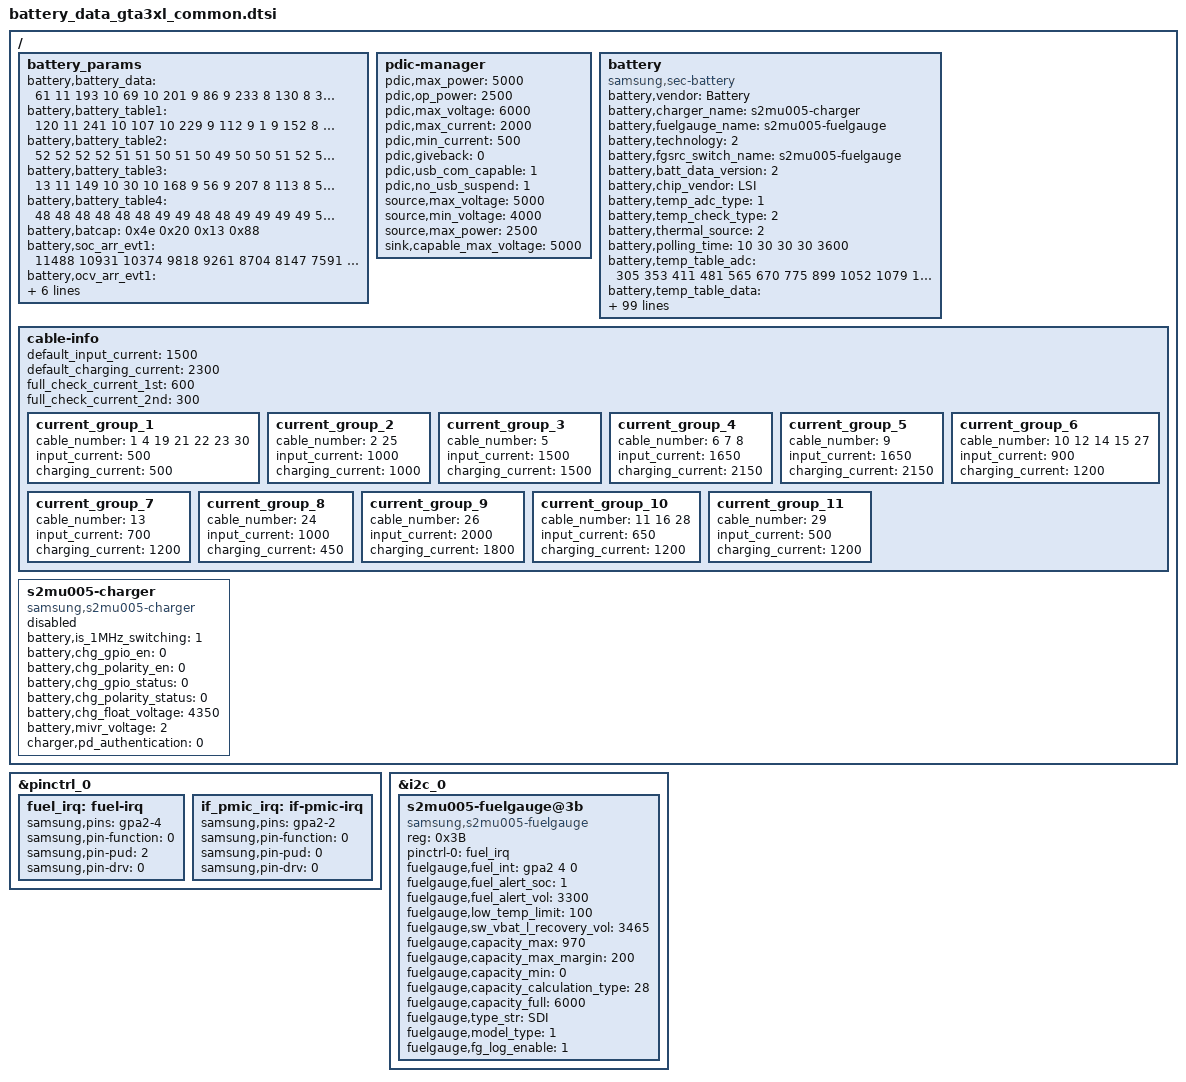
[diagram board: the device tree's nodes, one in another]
/*
 * Tab A3 2019 Battery parameters device tree file for board IDs 04 and higher
 *
 * Copyright (C) 2017 Samsung Electronics, Inc.
 *
 * This program is free software; you can redistribute it and/or
 * modify it under the terms of the GNU General Public License
 * as published by the Free Software Foundation; either version 2
 * of the License, or (at your option) any later version.
 *
 * This program is distributed in the hope that it will be useful,
 * but WITHOUT ANY WARRANTY; without even the implied warranty of
 * MERCHANTABILITY or FITNESS FOR A PARTICULAR PURPOSE.  See the
 * GNU General Public License for more details.
 *
 * You should have received a copy of the GNU General Public License
 * along with this program. If not, see <http://www.gnu.org/licenses/>.
 *
 */

/ {
	fragment@battery {
		target-path = "/";
		__overlay__ {
			battery_params {
					battery,battery_data =
					<
						/***** battery data for 4.35 *****/
						/* battery,battery_table3 */
						61 11 193 10 69 10 201 9 86 9
						233 8 130 8 34 8 204 7 116 7
						21 7 204 6 155 6 117 6 86 6
						58 6 20 6 238 5 183 5 139 5
						11 5 131 1 213 8 104 8 251 7
						142 7 33 7 180 6 71 6 218 5
						110 5 1 5 148 4 39 4 186 3
						77 3 224 2 115 2 7 2 154 1
						45 1 192 0 83 0 230 15

						/* battery,battery_table4 */
						10 10 10 10 10 10 96 97 96 96
						96 96 97 98 100 101 104 107 113 124
						138 86

						/* battery,batcap */
						0x5A 0x28 0x16 0x8A /* [0x0F] [0x0E] [0x11] [0x10] */
						/* battery,accum */
						0x00 0x8 /* [0x44] [0x45] */

						/* battery,soc_arr_val */
						11037 10506 9975 9443 8911 8380 7848 7317 6785 6253
						5722 5190 4659 4127 3595 3064 2532 2001 1469 937
						406 (-126)

						/* battery,ocv_arr_val */
						44046 43441 42835 42234 41670 41137 40637 40168 39748 39315
						38854 38497 38258 38072 37921 37782 37600 37410 37146 36928
						36302 31892

						/* battery,tunning */
						0x00

						/***** battery data for 4.33 *****/
						/* battery,battery_table3 */
						61 11 193 10 69 10 201 9 86 9
						233 8 130 8 34 8 204 7 116 7
						21 7 204 6 155 6 117 6 86 6
						58 6 20 6 238 5 183 5 139 5
						11 5 131 1 249 8 139 8 28 8
						174 7 63 7 209 6 98 6 244 5
						133 5 22 5 168 4 58 4 203 3
						93 3 238 2 127 2 17 2 162 1
						52 1 197 0 87 0 232 15

						/* battery,battery_table4 */
						51 51 97 97 97 97 96 97 96 96
						96 96 97 98 100 101 104 107 113 124
						138 206

						/* battery,batcap */
						0x59 0x10 0x16 0x44 /* [0x0F] [0x0E] [0x11] [0x10] */
						/* battery,accum */
						0x00 0x8 /* [0x44] [0x45] */

						/* battery,soc_arr_val */
						11217 10678 10138 9599 9059 8519 7980 7440 6899 6360
						5820 5281 4741 4202 3662 3122 2582 2043 1503 963
						423 (-115)
						/* battery,ocv_arr_val */
						44046 43441 42835 42234 41670 41137 40637 40168 39748 39315
						38854 38497 38258 38072 37921 37782 37600 37410 37146 36928
						36302 31892

						/* battery,tunning */
						0x00

						/***** battery data for 4.31 *****/
						/* battery,battery_table3 */
						61 11 193 10 69 10 201 9 86 9
						233 8 130 8 34 8 204 7 116 7
						21 7 204 6 155 6 117 6 86 6
						58 6 20 6 238 5 183 5 139 5
						11 5 131 1 54 9 196 8 83 8
						225 7 112 7 255 6 141 6 28 6
						170 5 57 5 199 4 86 4 229 3
						115 3 2 3 144 2 31 2 173 1
						60 1 202 0 89 0 232 15

						/* battery,battery_table4 */
						51 51 97 97 97 97 96 97 96 96
						96 96 97 98 100 101 104 107 113 124
						138 206

						/* battery,batcap */
						0x57 0x80 0x15 0xE0 /* [0x0F] [0x0E] [0x11] [0x10] */
						/* battery,accum */
						0x00 0x8 /* [0x44] [0x45] */

						/* battery,soc_arr_val */
						11512 10958 10404 9850 9297 8743 8189 7635 7080 6526
						5973 5419 4866 4312 3758 3204 2650 2096 1542 988
						434 (-119)
						/* battery,ocv_arr_val */
						44046 43441 42835 42234 41670 41137 40637 40168 39748 39315
						38854 38497 38258 38072 37921 37782 37600 37410 37146 36928
						36302 31892

						/* battery,tunning */
						0x00

						/***** battery data for 4.29 *****/
						/* battery,battery_table3 */
						61 11 193 10 69 10 201 9 86 9
						233 8 130 8 34 8 204 7 116 7
						21 7 204 6 155 6 117 6 86 6
						58 6 20 6 238 5 183 5 139 5
						11 5 131 1 155 9 37 9 174 8
						56 8 194 7 75 7 213 6 95 6
						232 5 114 5 252 4 133 4 15 4
						153 3 35 3 172 2 54 2 192 1
						73 1 211 0 93 0 231 15

						/* battery,battery_table4 */
						51 51 97 97 97 97 96 97 96 96
						96 96 97 98 100 101 104 107 113 124
						138 206

						/* battery,batcap */
						0x55 0xF0 0x15 0x7C /* [0x0F] [0x0E] [0x11] [0x10] */
						/* battery,accum */
						0x00 0x8 /* [0x44] [0x45] */

						/* battery,soc_arr_val */
						12007 11429 10851 10274 9696 9118 8541 7963 7385 6808
						6230 5652 5074 4497 3919 3342 2764 2186 1608 1031
						453 (-124)
						/* battery,ocv_arr_val */
						44046 43441 42835 42234 41670 41137 40637 40168 39748 39315
						38854 38497 38258 38072 37921 37782 37600 37410 37146 36928
						36302 31892

						/* battery,tunning */
						0x00

						/***** battery data for 4.24 *****/
						/* battery,battery_table3 */
						61 11 193 10 69 10 201 9 86 9
						233 8 130 8 34 8 204 7 116 7
						21 7 204 6 155 6 117 6 86 6
						58 6 20 6 238 5 183 5 139 5
						11 5 131 1 229 9 107 9 241 8
						120 8 254 7 132 7 10 7 144 6
						22 6 156 5 34 5 169 4 47 4
						181 3 59 3 193 2 71 2 205 1
						83 1 217 0 96 0 230 15

						/* battery,battery_table4 */
						51 51 97 97 97 97 96 97 96 96
						96 96 97 98 100 101 104 107 113 124
						138 206

						/* battery,batcap */
						0x52 0xD0 0x14 0xB4 /* [0x0F] [0x0E] [0x11] [0x10] */
						/* battery,accum */
						0x00 0x8 /* [0x44] [0x45] */

						/* battery,soc_arr_val */
						12369 11774 11178 10584 9988 9393 8798 8203 7608 7013
						6418 5823 5228 4633 4037 3442 2847 2252 1656 1062
						467 (-128)
						/* battery,ocv_arr_val */
						44046 43441 42835 42234 41670 41137 40637 40168 39748 39315
						38854 38497 38258 38072 37921 37782 37600 37410 37146 36928
						36302 31892

						/* battery,tunning */
						0x00
					>;

					battery,battery_table1 = <
							120 11 241 10 107 10 229 9 112 9
							1 9 152 8 41 8 195 7 134 7
							45 7 209 6 154 6 114 6 83 6
							58 6 29 6 246 5 193 5 145 5
							14 5 223 1 49 9 191 8 77 8
							219 7 105 7 247 6 132 6 19 6
							161 5 46 5 188 4 74 4 216 3
							102 3 244 2 130 2 16 2 158 1
							44 1 186 0 72 0 214 15
							>;

					battery,battery_table2 = <
							52 52 52 52 51 51 50 51 50 49
							50 50 51 52 54 56 60 64 73 87
							111 106
							>;

					battery,battery_table3 = <
							13 11 149 10 30 10 168 9 56 9
							207 8 113 8 5 8 187 7 97 7
							250 6 190 6 146 6 110 6 82 6
							53 6 18 6 233 5 180 5 136 5
							230 4 125 1 217 8 107 8 253 7
							144 7 34 7 180 6 71 6 217 5
							107 5 254 4 144 4 34 4 180 3
							71 3 217 2 107 2 254 1 144 1
							34 1 181 0 71 0 217 15
							>;

					battery,battery_table4 = <
							48 48 48 48 48 48 49 49 48 48
							49 49 49 49 50 50 50 50 51 52
							56 96
							>;

					battery,batcap = <0x4e 0x20 0x13 0x88>; /* [0x0F] [0x0E] [0x11] [0x10] */

					battery,soc_arr_evt1 = <
								11488 10931 10374 9818 9261 8704 8147 7591 7034 6477
								5920 5363 4807 4250 3693 3136 2580 2023 1466 910
								353 (-204)
								>;
					battery,ocv_arr_evt1 = <
								44335 43678 43021 42368 41795 41254 40740 40199 39701 39405
								38972 38521 38253 38059 37907 37785 37640 37452 37193 36957
								36319 32338
								>;

					battery,soc_arr_evt2 = <
								11059 10523 9987 9452 8916 8381 7845 7309 6774 6238
								5703 5167 4631 4096 3560 3025 2489 1953 1418 882
								347 (-189)
								>;
					battery,ocv_arr_evt2 = <
								43812 43230 42648 42069 41524 41009 40553 40025 39665 39223
								38722 38430 38213 38039 37900 37761 37586 37387 37128 36914
								36123 31861
								>;

					battery,FG_Accumulative_rate_evt2 = <0x00 0x8>; /* 0x44 0x45 */
			};

			pdic-manager {
				/* sink */
				pdic,max_power = <5000>;
				pdic,op_power = <2500>;
				pdic,max_voltage = <6000>;
				pdic,max_current = <2000>;
				pdic,min_current = <500>;

				pdic,giveback = <0>;
				pdic,usb_com_capable = <1>;
				pdic,no_usb_suspend = <1>;

				/* source */
				source,max_voltage = <5000>;
				source,min_voltage = <4000>;
				source,max_power = <2500>;

				/* sink cap */
				sink,capable_max_voltage = <5000>;
			};

			battery {
				status = "okay";
				compatible = "samsung,sec-battery";

				pinctrl-names = "default";

				battery,vendor = "Battery";
				battery,charger_name = "s2mu005-charger";
				battery,fuelgauge_name = "s2mu005-fuelgauge";
				battery,technology = <2>; /* POWER_SUPPLY_TECHNOLOGY_LION */
				battery,fgsrc_switch_name = "s2mu005-fuelgauge"; /* Fuelgauge voltage source */

				battery,batt_data_version = <2>;

				battery,chip_vendor = "LSI";
				battery,temp_adc_type = <1>; /* SEC_BATTERY_ADC_TYPE_AP */

				battery,temp_check_type = <2>; /* SEC_BATTERY_TEMP_CHECK_TEMP */

				battery,thermal_source = <2>; /* SEC_BATTERY_THERMAL_SOURCE_ADC */

				battery,polling_time = <10 30 30 30 3600>;

				battery,temp_table_adc = <
							305 353 411 481 565 670 775 899 1052 1079
							1220 1359 1401 1446 1468 1488 1508 1533 1563 1596
							1644 1700 1822 2056 2289 2416 2518 2656 2742 2873
							2964 3091 3166 3205 3239 3275 3309 3342 3492 3615
							3717
							>;
				battery,temp_table_data = <
							900 850 800 750 700 650 600 550 500 480
							450 410 400 390 380 370 360 350 340 330
							320 310 300 250 200 170 150 120 100 70
							50 20 0 (-10) (-20) (-30) (-40) (-50) (-100) (-150)
							(-200)
							>;

				battery,inbat_voltage = <1>;

				battery,inbat_voltage_table_adc = <
								2766 2755 2728 2698 2678 2649 2620 2598 2562 2532
								2508 2475 2448 2429 2401 2370 2348 2318 2288 2258
								>;
				battery,inbat_voltage_table_data = <
								4350 4300 4250 4200 4150 4100 4050 4000 3950 3900
								3850 3800 3750 3700 3650 3600 3550 3500 3450 3400
								>;

				battery,adc_check_count = <5>;

				battery,cable_check_type = <4>; /* SEC_BATTERY_CABLE_CHECK_PSY */
				battery,cable_source_type = <1>; /* SEC_BATTERY_CABLE_SOURCE_EXTERNAL */
				battery,polling_type = <1>; /* SEC_BATTERY_MONITOR_ALARM */
				battery,monitor_initial_count = <0>;

				battery,pre_afc_input_current = <500>;

				battery,battery_check_type = <0>; /* SEC_BATTERY_CHECK_NONE */
				battery,check_count = <0>;

				battery,ovp_uvlo_check_type = <3>; /* SEC_BATTERY_OVP_UVLO_CHGPOLLING */

				battery,temp_check_count = <1>;
				battery,temp_highlimit_threshold_event = <800>;
				battery,temp_highlimit_recovery_event = <750>;
				battery,temp_high_threshold_event = <500>;
				battery,temp_high_recovery_event = <450>;
				battery,temp_low_threshold_event = <0>;
				battery,temp_low_recovery_event = <50>;
				battery,temp_highlimit_threshold_normal = <800>;
				battery,temp_highlimit_recovery_normal = <750>;
				battery,temp_high_threshold_normal = <500>;
				battery,temp_high_recovery_normal = <450>;
				battery,temp_low_threshold_normal = <0>;
				battery,temp_low_recovery_normal = <50>;
				battery,temp_highlimit_threshold_lpm = <800>;
				battery,temp_highlimit_recovery_lpm = <750>;
				battery,temp_high_threshold_lpm = <500>;
				battery,temp_high_recovery_lpm = <450>;
				battery,temp_low_threshold_lpm = <0>;
				battery,temp_low_recovery_lpm = <50>;
				battery,wpc_high_threshold_normal = <450>;
				battery,wpc_high_recovery_normal = <400>;
				battery,wpc_low_threshold_normal = <0>;
				battery,wpc_low_recovery_normal = <50>;

				battery,full_check_type = <2>; /* SEC_BATTERY_FULLCHARGED_FG_CURRENT */
				battery,full_check_type_2nd = <2>; /* SEC_BATTERY_FULLCHARGED_FG_CURRENT */
				battery,full_check_count = <1>;
				battery,chg_gpio_full_check = <0>;
				battery,chg_polarity_full_check = <1>;

				/* SEC_BATTERY_FULL_CONDITION_SOC |
				* SEC_BATTERY_FULL_CONDITION_NOTIMEFULL |
				* SEC_BATTERY_FULL_CONDITION_VCELL
				*/
				battery,full_condition_type = <13>;
				battery,full_condition_soc = <93>;
				battery,full_condition_vcell = <4200>;

				battery,recharge_check_count = <1>;
				battery,recharge_condition_type = <4>; /* SEC_BATTERY_RECHARGE_CONDITION_VCELL */
				battery,recharge_condition_soc = <98>;
				battery,recharge_condition_vcell = <4250>;

				battery,charging_total_time = <14400>;
				battery,hv_charging_total_time = <10800>;
				battery,normal_charging_total_time = <18000>;
				battery,usb_charging_total_time = <36000>;
				battery,recharging_total_time = <5400>;
				battery,charging_reset_time = <0>;

				battery,chg_float_voltage = <4350>;

				battery,swelling_high_temp_block = <410>;
				battery,swelling_high_temp_recov = <390>;
				battery,swelling_wc_high_temp_recov = <390>;
				battery,swelling_low_temp_block_1st = <150>;
				battery,swelling_low_temp_recov_1st = <200>;
				battery,swelling_low_temp_block_2nd = <50>;
				battery,swelling_low_temp_recov_2nd = <100>;

				battery,swelling_low_temp_current = <1200>;	/* 0.3C */
				battery,swelling_low_temp_topoff = <300>;	/* 0.05C */
				battery,swelling_high_temp_current = <1800>;	/* 0.45C */
				battery,swelling_high_temp_topoff = <300>;	/* 0.05C */
				battery,swelling_wc_high_temp_current = <750>;	/* 0.3C */
				battery,swelling_wc_low_temp_current = <750>;	/* 0.3C */

				battery,swelling_drop_float_voltage = <4150>;
				battery,swelling_high_rechg_voltage = <4000>;
				battery,swelling_low_rechg_voltage = <4000>;

				battery,siop_event_check_type = <1>;
				battery,siop_call_cv_current = <330>;
				battery,siop_call_cc_current = <330>;

				battery,siop_input_limit_current = <1200>;
				battery,siop_charging_limit_current = <1000>;

				battery,battery_full_capacity = <6000>;

				/* cycle, chg_float_voltage, recharge_condition_vcell, full_condition_vcell, full_condition_soc */
				battery,age_data = <0 4350 4250 4250 93	/*4.35*/
						300 4330 4230 4230 92	/*4.33*/
						400 4310 4210 4210 91	/*4.31*/
						700 4290 4190 4190 90	/*4.29*/
						1000 4240 4140 4140 89	/*4.24*/
						>;

				battery,max_input_voltage = <5000>; /* mV */
				battery,max_input_current = <2000>;  /* mA */
				battery,pd_charging_charge_power = <10000>;
				battery,max_charging_current = <2300>;
				battery,slow_charging_current = <1000>;

				battery,standard_curr = <1551>;
				battery,expired_time = <20700>; /* 245 + 100 minutes */
				battery,recharging_expired_time = <5400>;

				battery,ttf_pd_charge_current = <1700>;
				battery,ttf_rp3_charge_current = <1700>;
				battery,ttf_capacity = <5970>;
				battery,cv_data = <
							1481	734	2695
							1372	745	2539
							1264	755	2389
							1169	765	2220
							1075	775	2040
							973		784	1860
							884		794	1650
							795		805	1440
							743		815	1290
							687		826	1139
							645		833	1049
							623		844	959
							603		854	899
							575		867	809
							561		875	749
							540		886	659
							527		893	600
							498		906	480
							476		915	390
							456		924	300
							441		932	210
							433		942	180
							427		952	150
							422		963	120
							416		972	90
							413		983	60
							404		992	30
							398		1000	0
							>;

				battery,cisd_max_voltage_thr = <5000>; /* battery ovp detection voltage */

				battery,enable_water_resistance;

				battery,cisd_alg_index = <7>;

				io-channels = <&exynos_adc 1>, <&exynos_adc 2>;
				io-channel-names = "adc-temp", "adc-in-bat";
				#io-channel-cells = <5>;
				io-channel-ranges;
			};

	/* sec_battery_cable
	 *   0	UNKNOWN,
	 *   1	NONE,
	 *   2	PREPARE_TA,
	 *   3	TA,
	 *   4	USB,
	 *   5	USB_CDP,
	 *   6	9V_TA,
	 *   7	9V_ERR,
	 *   8	9V_UNKNOWN,
	 *   9	12V_TA,
	 *  10	WIRELESS,
	 *  11	HV_WIRELESS,
	 *  12	PMA_WIRELESS,
	 *  13	WIRELESS_PACK,
	 *  14	WIRELESS_PACK_TA,
	 *  15	WIRELESS_STAND,
	 *  16	WIRELESS_HV_STAND,
	 *  17	QC20,
	 *  18	QC30,
	 *  19	PDIC,
	 *  20	UARTOFF,
	 *  21	OTG,
	 *  22	LAN_HUB,
	 *  23	POWER_SHARING,
	 *  24	HMT_CONNECTED,
	 *  25	HMT_CHARGE,
	 *  26	HV_TA_CHG_LIMIT,
	 *  27	WIRELESS_VEHICLE,
	 *  28	WIRELESS_HV_VEHICLE,
	 *  29	PREPARE_WIRELESS_HV,
	 *  30	TIMEOUT,
	 *  31	CABLE_MAX,
	 */
			cable-info {
				default_input_current = <1500>;
				default_charging_current = <2300>;
				full_check_current_1st = <600>;
				full_check_current_2nd = <300>;

				current_group_1 {
					cable_number = <1 4 19 21 22 23 30>;
					input_current = <500>;
					charging_current = <500>;
				};

				current_group_2 {
					cable_number = <2 25>;
					input_current = <1000>;
					charging_current = <1000>;
				};

				current_group_3 {
					cable_number = <5>;
					input_current = <1500>;
					charging_current = <1500>;
				};

				current_group_4 {
					cable_number = <6 7 8>;
					input_current = <1650>;
					charging_current = <2150>;
				};

				current_group_5 {
					cable_number = <9>;
					input_current = <1650>;
					charging_current = <2150>;
				};

				current_group_6 {
					cable_number = <10 12 14 15 27>;
					input_current = <900>;
					charging_current = <1200>;
				};

				current_group_7 {
					cable_number = <13>;
					input_current = <700>;
					charging_current = <1200>;
				};

				current_group_8 {
					cable_number = <24>;
					input_current = <1000>;
					charging_current = <450>;
				};

				current_group_9 {
					cable_number = <26>;
					input_current = <2000>;
					charging_current = <1800>;
				};

				current_group_10 {
					cable_number = <11 16 28>;
					input_current = <650>;
					charging_current = <1200>;
				};

				current_group_11 {
					cable_number = <29>;
					input_current = <500>;
					charging_current = <1200>;
				};
			};

			s2mu005-charger {
				status = "disable";
				compatible = "samsung,s2mu005-charger";
				battery,is_1MHz_switching = <1>;
				battery,chg_gpio_en = <0>;
				battery,chg_polarity_en = <0>;
				battery,chg_gpio_status = <0>;
				battery,chg_polarity_status = <0>;
				battery,chg_float_voltage = <4350>;
				battery,mivr_voltage = <2>; /* 0:  4200, 1 : 4300, 2 : 4400 ..... 7: 4900 */
				charger,pd_authentication = <0>;
			};
		};
	};
};

&pinctrl_0 {
	fuel_irq: fuel-irq {
		samsung,pins = "gpa2-4";
		samsung,pin-function = <0>;
		samsung,pin-pud = <2>;
		samsung,pin-drv = <0>;
	};

	if_pmic_irq: if-pmic-irq {
		samsung,pins = "gpa2-2";
		samsung,pin-function = <0>;
		samsung,pin-pud = <0>;
		samsung,pin-drv = <0>;
	};
};

&i2c_0 {
	status = "okay";
	s2mu005-fuelgauge@3b {
		compatible = "samsung,s2mu005-fuelgauge";
		reg = <0x3B>;
		pinctrl-names = "default";
		pinctrl-0 = <&fuel_irq>;
		fuelgauge,fuel_int = <&gpa2 4 0>;
		fuelgauge,fuel_alert_soc = <1>;
		fuelgauge,fuel_alert_vol = <3300>;
		fuelgauge,low_temp_limit = <100>;
		fuelgauge,sw_vbat_l_recovery_vol = <3465>;
		fuelgauge,capacity_max = <970>;
		fuelgauge,capacity_max_margin = <200>;
		fuelgauge,capacity_min = <0>;
		fuelgauge,capacity_calculation_type = <28>;
		fuelgauge,capacity_full = <6000>;
		fuelgauge,type_str = "SDI";
		fuelgauge,model_type = <1>;
		fuelgauge,fg_log_enable = <1>;
	};
};
